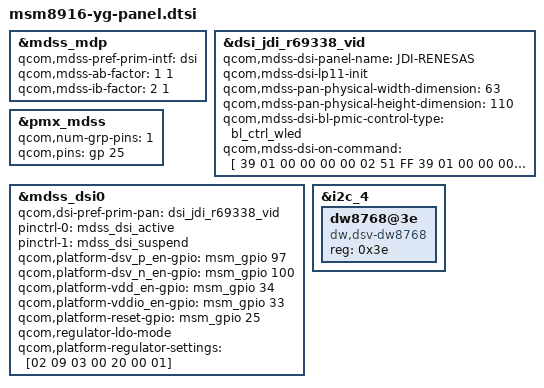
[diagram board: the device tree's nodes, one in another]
/* Copyright (c) 2013, Code Aurora Forum. All rights reserved.
 *
 * This program is free software; you can redistribute it and/or modify
 * it under the terms of the GNU General Public License version 2 and
 * only version 2 as published by the Free Software Foundation.
 *
 * This program is distributed in the hope that it will be useful,
 * but WITHOUT ANY WARRANTY; without even the implied warranty of
 * MERCHANTABILITY or FITNESS FOR A PARTICULAR PURPOSE.  See the
 * GNU General Public License for more details.
 */

#include "../msm8916-lge-common/dsi-panel-jdi-hd-video.dtsi"

&mdss_mdp {
       qcom,mdss-pref-prim-intf = "dsi";
       qcom,mdss-ab-factor = <1 1>;
       qcom,mdss-ib-factor = <2 1>;
};

&dsi_jdi_r69338_vid {
       qcom,mdss-dsi-panel-name = "JDI-RENESAS";
       qcom,mdss-dsi-lp11-init;
       qcom,mdss-pan-physical-width-dimension = <63>;
       qcom,mdss-pan-physical-height-dimension = <110>;
       qcom,mdss-dsi-bl-pmic-control-type = "bl_ctrl_wled";
       qcom,mdss-dsi-on-command = [
		39 01 00 00 00 00 02
		51 FF

		39 01 00 00 00 00 02
		53 0C			//BCTRL Off (2c => 0c)

		39 01 00 00 00 00 02
		55 00			//SRE Off (40 => 00)

		29 01 00 00 00 00 02
		B0 04

		29 01 00 00 00 00 2D
		C1 84 61 00 52 4A 59
		94 20 03 1C D9 D8 82
		CF B9 07 17 6B D1 80
		41 82 94 52 4A 09 11
		11 11 11 A0 40 42 20
		12 10 22 00 15 00 01
		00 00 00

		29 01 00 00 00 00 10
		C4 70 00 00 00 00 00
		00 00 00 00 06 16 16
		16 01

		29 01 00 00 00 00 0D
		CB F0 F7 FF 3F 30 00
		00 00 00 00 3C CF

		29 01 00 00 00 00 1F /* gamma setting 1 */
		C7 00 0A 16 20 2C 39
		43 52 36 3E 4B 58 5A
		5F 67 00 0A 16 20 2C
		39 43 52 36 3E 4B 58
		5A 5F 67

		29 01 00 00 00 00 14 /* gamma setting 2 */
		C8 00 00 00 00 00 FC
		00 00 00 00 00 FC 00
		00 00 00 00 FC 00

		29 01 00 00 00 00 21 /* Color Enhancement */
		CA 01 70 9A 95 A2 98
		95 8F 3F 3F 80 80 08
		80 08 3F 08 90 0C 0C
		0A 06 04 04 00 C8 10
		10 3F 3F 3F 3F

		29 01 00 00 00 00 02
		D6 01

		15 01 00 00 00 00 02
		36 00

		05 01 00 00 00 00 01
		29

		05 01 00 00 78 00 01
		11
    ];
};

&pmx_mdss {
       qcom,num-grp-pins = <1>;
       qcom,pins = <&gp 25>;
};

&mdss_dsi0 {
       qcom,dsi-pref-prim-pan = <&dsi_jdi_r69338_vid>;
       pinctrl-names = "mdss_default", "mdss_sleep";
       pinctrl-0 = <&mdss_dsi_active>;
       pinctrl-1 = <&mdss_dsi_suspend>;

       qcom,platform-dsv_p_en-gpio = <&msm_gpio 97 0>;
       qcom,platform-dsv_n_en-gpio = <&msm_gpio 100 0>;
       qcom,platform-vdd_en-gpio = <&msm_gpio 34 0>;
       qcom,platform-vddio_en-gpio = <&msm_gpio 33 0>;

       qcom,platform-reset-gpio = <&msm_gpio 25 0>;
       qcom,regulator-ldo-mode;
       qcom,platform-regulator-settings = [02 09 03 00 20 00 01];

};

&i2c_4 {
	dw8768@3e {
		compatible = "dw,dsv-dw8768";
		status = "ok";
		reg = <0x3e>;
	};
};

